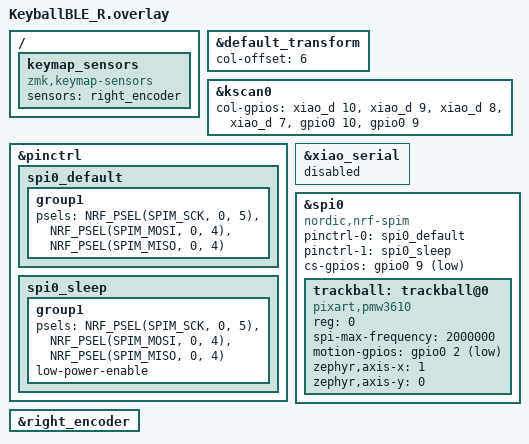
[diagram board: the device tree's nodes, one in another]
#include "KeyballBLE.dtsi"

&default_transform {
    /* 7から6に修正：これでPがLになるような横ズレが直ります */
    col-offset = <6>;
};

&kscan0 {
    col-gpios
        = <&xiao_d 10 GPIO_ACTIVE_HIGH>
        , <&xiao_d 9 GPIO_ACTIVE_HIGH> 
        , <&xiao_d 8 GPIO_ACTIVE_HIGH> 
        , <&xiao_d 7 GPIO_ACTIVE_HIGH> 
        , <&gpio0 10 GPIO_ACTIVE_HIGH>
        , <&gpio0 9 GPIO_ACTIVE_HIGH>  /* ここを gpio0 9 に修正 */
        ;
};

/* つまみをシステムに登録する新しい書き方 */
/ {
    keymap_sensors: keymap_sensors {
        compatible = "zmk,keymap-sensors";
        sensors = <&right_encoder>;
    };
};

&pinctrl {
    spi0_default: spi0_default {
        group1 {
            psels = <NRF_PSEL(SPIM_SCK, 0, 5)>,
                <NRF_PSEL(SPIM_MOSI, 0, 4)>,
                <NRF_PSEL(SPIM_MISO, 0, 4)>;
        };
    };

    spi0_sleep: spi0_sleep {
        group1 {
            psels = <NRF_PSEL(SPIM_SCK, 0, 5)>,
                <NRF_PSEL(SPIM_MOSI, 0, 4)>,
                <NRF_PSEL(SPIM_MISO, 0, 4)>;
            low-power-enable;
        };
    };
};

&xiao_serial { status = "disabled"; };

&spi0 {
    status = "okay";
    compatible = "nordic,nrf-spim";
    pinctrl-0 = <&spi0_default>;
    pinctrl-1 = <&spi0_sleep>;
    pinctrl-names = "default", "sleep";
    cs-gpios = <&gpio0 9 GPIO_ACTIVE_LOW>;

    trackball: trackball@0 {
        status = "okay";
        compatible = "pixart,pmw3610";
        reg = <0>;
        spi-max-frequency = <2000000>;
        motion-gpios = <&gpio0 2 (GPIO_ACTIVE_LOW | GPIO_PULL_UP)>;
        zephyr,axis-x = <1>; 
        zephyr,axis-y = <0>;
    };
};

/* 右側のつまみを有効化 */
&right_encoder {
    status = "okay";
};
